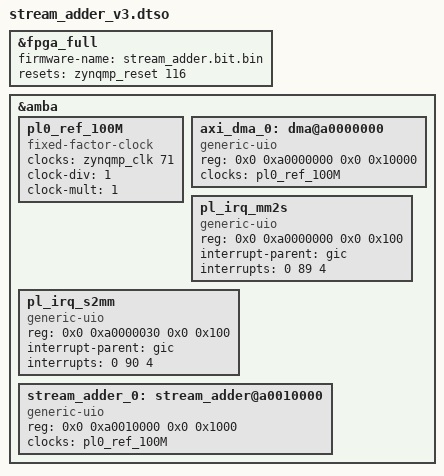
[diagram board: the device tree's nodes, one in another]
/*
 * stream_adder_v3.dtso - Version final con UIO IRQs expuestas a userspace
 *
 * Cambios v3 vs v2:
 * - axi_dma_0 SIN interrupts (evita conflicto con UIO nodes)
 * - Nuevos UIO nodes pl_irq_mm2s y pl_irq_s2mm con interrupts
 *   → se exponen como /dev/uioN para userspace (read() blocking)
 * - stream_adder_0 sin cambios (generic-uio para registro AXI-Lite)
 */

/dts-v1/;
/plugin/;

&fpga_full {
    #address-cells = <2>;
    #size-cells = <2>;
    firmware-name = "stream_adder.bit.bin";
    resets = <&zynqmp_reset 116>;
};

&amba {
    #address-cells = <2>;
    #size-cells = <2>;

    /* Clock fabric PS -> PL, SIN reprogramar el PLL (fix del v2) */
    pl0_ref_100M: pl0_ref_100M {
        #clock-cells = <0>;
        compatible = "fixed-factor-clock";
        clocks = <&zynqmp_clk 71>;    /* pl_clk0 */
        clock-div = <1>;
        clock-mult = <1>;
    };

    /*
     * AXI DMA registers - solo mmio, SIN interrupts.
     * Las IRQs se manejan via los UIO nodes pl_irq_* debajo.
     * El usuario controla el DMA escribiendo en sus registros via /dev/mem
     * o mejor, con uio_stream_adder + mmap desde userspace.
     */
    axi_dma_0: dma@a0000000 {
        compatible = "generic-uio";
        reg = <0x0 0xa0000000 0x0 0x10000>;
        clocks = <&pl0_ref_100M>;
        clock-names = "clk";
    };

    /*
     * UIO para IRQ del MM2S (canal Memory-to-Stream).
     * Cuando DMA termina una transferencia MM2S, dispara SPI 89 = GIC 121.
     * Userspace: read(/dev/uio_mm2s) -> bloquea hasta que IRQ llegue.
     */
    pl_irq_mm2s: pl_irq_mm2s {
        compatible = "generic-uio";
        reg = <0x0 0xa0000000 0x0 0x100>;  /* dummy reg para que UIO mapee algo */
        interrupt-parent = <&gic>;
        interrupts = <0 89 4>;             /* SPI 89 -> GIC 121 */
    };

    /*
     * UIO para IRQ del S2MM (canal Stream-to-Memory).
     */
    pl_irq_s2mm: pl_irq_s2mm {
        compatible = "generic-uio";
        reg = <0x0 0xa0000030 0x0 0x100>;
        interrupt-parent = <&gic>;
        interrupts = <0 90 4>;             /* SPI 90 -> GIC 122 */
    };

    /*
     * stream_adder - registro AXI-Lite de control (reg0 = add_value).
     */
    stream_adder_0: stream_adder@a0010000 {
        compatible = "generic-uio";
        reg = <0x0 0xa0010000 0x0 0x1000>;
        clocks = <&pl0_ref_100M>;
        clock-names = "clk";
    };
};
